# SD24_B3_2 register map
Vendor: Texas Instruments
Peripheral module from a debugger description file (folder msp430).
Registers are 16-bit, read-write, reset 0x0 unless marked. A register's access mark holds for its fields unless they carry their own. Offsets are as the file gives them; lines under a group give offsets from that group; [hi:lo] are bit positions; {n}, {i} and the like mark numbered series; 'fields as' and 'values as' point back to an identical list; <NAME> marks a mode.

## SD24_B3
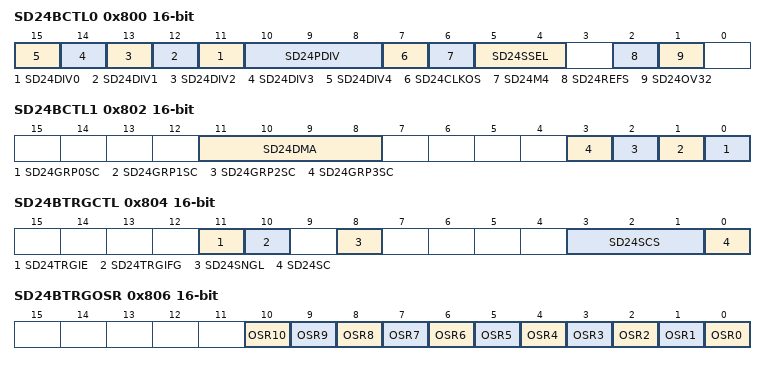
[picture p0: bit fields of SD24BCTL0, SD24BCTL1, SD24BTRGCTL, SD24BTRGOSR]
0x800 SD24BCTL0 — SD24B Control Register 0
  [n+11] SD24DIV{n} (n=0..4) — SD24B Frequency Divider Bit {n}
  [10:8] SD24PDIV — SD24B Frequency pre-scaler Bit 0
    0=SD24B Frequency pre-scaler /1; 1=SD24B Frequency pre-scaler /2; 2=SD24B Frequency pre-scaler /4; 3=SD24B Frequency pre-scaler /8; 4=SD24B Frequency pre-scaler /16; 5=SD24B Frequency pre-scaler /32; 6=SD24B Frequency pre-scaler /64; 7=SD24B Frequency pre-scaler /128
  [7] SD24CLKOS — SD24B Clock Output Select
  [6] SD24M4 — SD24B Modulator clock to Manchester decoder clock ratio
  [5:4] SD24SSEL — SD24B Clock Source Select 0
    0=SD24B Clock Source Select MCLK; 1=SD24B Clock Source Select SMCLK; 2=SD24B Clock Source Select ACLK; 3=SD24B Clock Source Select TACLK
  [2] SD24REFS — SD24B Reference Select
  [1] SD24OV32 — SD24B Overflow Control
0x802 SD24BCTL1 — SD24B Control Register 1
  [11:8] SD24DMA — SD24B DMA Trigger Select Bit 0
    {v}=SD24B DMA Trigger: {v} (v=0..8)
  [n] SD24GRP{n}SC (n=0..3) — SD24B Group {n} Start Conversion
0x804 SD24BTRGCTL — SD24B Trigger Control Register
  [11] SD24TRGIE — SD24B Trigger Interrupt Enable
  [10] SD24TRGIFG — SD24B Trigger Interrupt Flag
  [8] SD24SNGL — SD24B Single Trigger Mode
  [3:1] SD24SCS — SD24B Start Conversion Select Bit 0
    {v}=SD24B Start Conversion Select: {v} (v=0..7)
  [0] SD24SC — SD24B Start Conversion
0x806 SD24BTRGOSR — SD24B Trigger OSR Control Register
  [n] OSR{n} (n=0..10) — SD24B Oversampling Rate Bit: {n}
0x808 SD24BTRGPRE access not given reset not defined — SD24B Trigger Preload Register
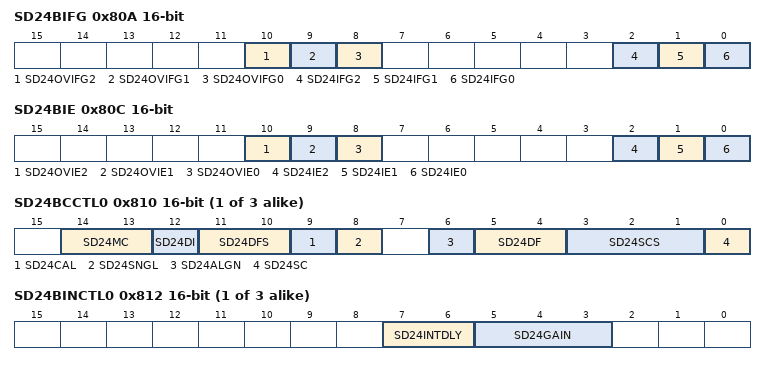
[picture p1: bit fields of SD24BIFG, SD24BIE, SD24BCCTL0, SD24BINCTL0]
0x80A SD24BIFG — SD24B Interrupt Flag Register
  [10] SD24OVIFG2 — SD24B Channel 2 Overflow Interrupt Flag
  [9] SD24OVIFG1 — SD24B Channel 1 Overflow Interrupt Flag
  [8] SD24OVIFG0 — SD24B Channel 0 Overflow Interrupt Flag
  [2] SD24IFG2 — SD24B Channel 2 Interrupt Flag
  [1] SD24IFG1 — SD24B Channel 1 Interrupt Flag
  [0] SD24IFG0 — SD24B Channel 0 Interrupt Flag
0x80C SD24BIE — SD24B Interrupt Enable Register
  [10] SD24OVIE2 — SD24B Channel 2 Overflow Interrupt Enable
  [9] SD24OVIE1 — SD24B Channel 1 Overflow Interrupt Enable
  [8] SD24OVIE0 — SD24B Channel 0 Overflow Interrupt Enable
  [2] SD24IE2 — SD24B Channel 2 Interrupt Enable
  [1] SD24IE1 — SD24B Channel 1 Interrupt Enable
  [0] SD24IE0 — SD24B Channel 0 Interrupt Enable
0x80E SD24BIV access not given reset not defined — SD24B Interrupt Vector Register
{0x810+8i} SD24BCCTL{i} (i=0..2) — SD24B Channel {i} Control Register
  [14:13] SD24MC — SD24B Manchaster Encoding Bit: 0
    {v}=SD24B Manchaster Encoding {v} (v=0..3)
  [12] SD24DI — SD24B Digital Bitstream Input
  [11:10] SD24DFS — SD24B Digital Filter Bit: 0
    {v}=SD24B Digital Filter {v} (v=0..3)
  [9] SD24CAL — SD24B Calibration
  [8] SD24SNGL — SD24B Single Trigger Mode
  [6] SD24ALGN — SD24B Data Alignment
  [5:4] SD24DF — SD24B Data Format Bit: 0
    0=SD24B Data Format: Offset Binary; 1=SD24B Data Format: 2's complement
  [3:1] SD24SCS — SD24B Start Conversion Select Bit 0
    {v}=SD24B Start Conversion Select: {v} (v=0..7)
  [0] SD24SC — SD24B Start Conversion
{0x812+8i} SD24BINCTL{i} (i=0..2) — SD24B Channel {i} Input Control Register
  [7:6] SD24INTDLY — SD24B Interrupt Delay after 1.Conversion 0
    0=SD24B Interrupt Delay: Int. after 4.Conversion; 1=SD24B Interrupt Delay: Int. after 3.Conversion; 2=SD24B Interrupt Delay: Int. after 2.Conversion; 3=SD24B Interrupt Delay: Int. after 1.Conversion
  [5:3] SD24GAIN — SD24B Input Pre-Amplifier Gain Select 0
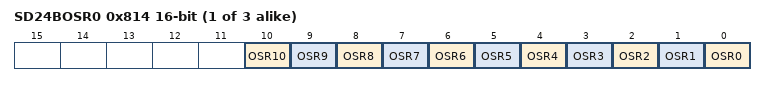
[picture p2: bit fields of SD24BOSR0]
{0x814+8i} SD24BOSR{i} (i=0..2) — SD24B Channel {i} OSR Control Register
  [n] OSR{n} (n=0..10) — SD24B Oversampling Rate Bit: {n}
{0x816+8i} SD24BPRE{i} access not given reset not defined (i=0..2) — SD24B Channel {i} Preload Register
{0x850+4i} SD24BMEML{i} access not given reset not defined (i=0..2) — SD24B Channel {i} Conversion Memory Low word
{0x852+4i} SD24BMEMH{i} access not given reset not defined (i=0..2) — SD24B Channel {i} Conversion Memory High Word
